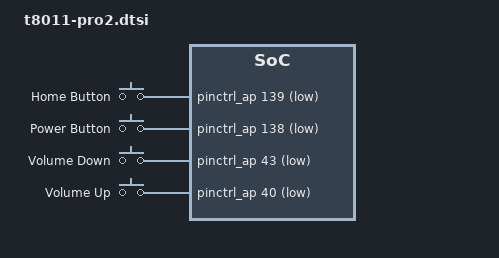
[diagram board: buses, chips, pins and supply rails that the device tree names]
// SPDX-License-Identifier: GPL-2.0+ OR MIT
/*
 * Apple iPad Pro 2 common device tree
 *
 * Copyright (c) 2022, Konrad Dybcio <konradybcio@kernel.org>
 */

#include <dt-bindings/input/input.h>

/ {
	chassis-type = "tablet";

	gpio-keys {
		compatible = "gpio-keys";

		button-home {
			label = "Home Button";
			gpios = <&pinctrl_ap 139 GPIO_ACTIVE_LOW>;
			linux,code = <KEY_HOMEPAGE>;
			wakeup-source;
		};

		button-power {
			label = "Power Button";
			gpios = <&pinctrl_ap 138 GPIO_ACTIVE_LOW>;
			linux,code = <KEY_POWER>;
			wakeup-source;
		};

		button-voldown {
			label = "Volume Down";
			gpios = <&pinctrl_ap 43 GPIO_ACTIVE_LOW>;
			linux,code = <KEY_VOLUMEDOWN>;
		};

		button-volup {
			label = "Volume Up";
			gpios = <&pinctrl_ap 40 GPIO_ACTIVE_LOW>;
			linux,code = <KEY_VOLUMEUP>;
		};
	};
};
